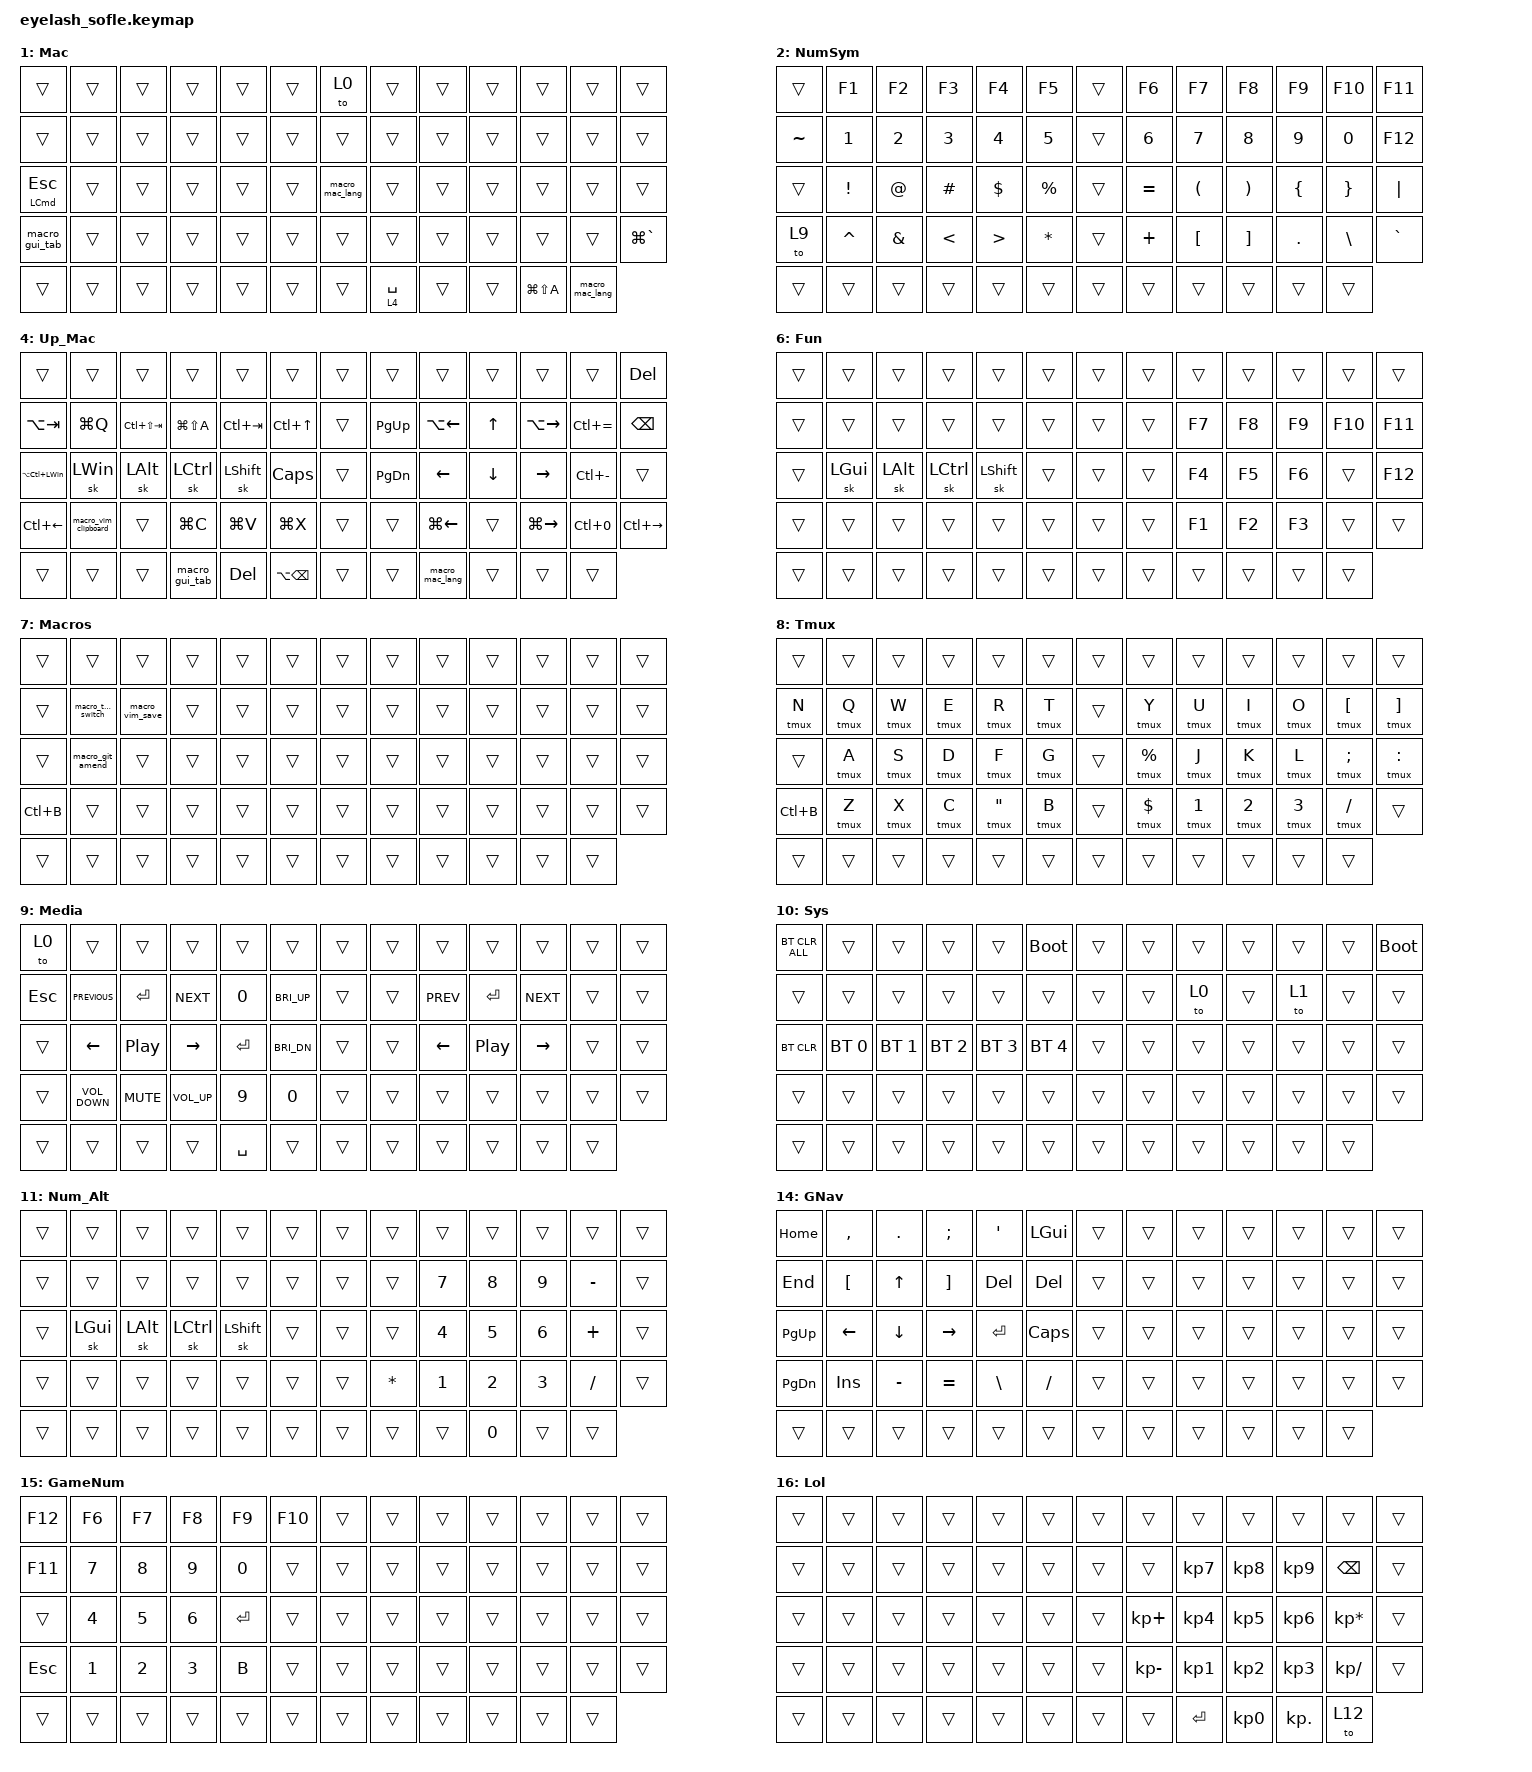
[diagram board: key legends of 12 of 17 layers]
#define ZMK_POINTING_DEFAULT_MOVE_VAL 1200  // 600
#define ZMK_POINTING_DEFAULT_SCRL_VAL 25   // 10

#include <input/processors.dtsi>
#include <zephyr/dt-bindings/input/input-event-codes.h>
#include <behaviors/tempo.dtsi>
#include <behaviors.dtsi>
#include <dt-bindings/zmk/bt.h>
#include <dt-bindings/zmk/keys.h>
#include <dt-bindings/zmk/pointing.h>

&mmv_input_listener { input-processors = <&zip_xy_scaler 2 1>; };

&msc_input_listener { input-processors = <&zip_scroll_scaler 2 1>; };

&msc {
    acceleration-exponent = <1>;      // 0
    time-to-max-speed-ms = <100>;       // 300
    delay-ms = <0>;                   // 0
};

&mmv {
    time-to-max-speed-ms = <500>;
    acceleration-exponent = <1>;
    trigger-period-ms = <16>;
};

&sk { quick-release; };

/ {
    scroll_encoder: scroll_encoder {
        compatible = "zmk,behavior-sensor-rotate";
        #sensor-binding-cells = <0>;
        bindings = <&msc SCRL_DOWN>, <&msc SCRL_UP>;

        tap-ms = <100>;
    };

    hml: homerow_mods_left {
        compatible = "zmk,behavior-hold-tap";
        label = "HOMEROW_MODS_LEFT_HAND";
        bindings = <&kp>, <&kp>;

        #binding-cells = <2>;
        tapping-term-ms = <200>;
        quick-tap-ms = <175>;
        require-prior-idle-ms = <115>;
        flavor = "balanced";
        hold-trigger-key-positions = <7 20 33 46 47 48 49 50 51 38 37 35 36 34 21 22 23 24 25 12 11 10 9 8 60 61 62 63 59>;
        hold-trigger-on-release;
    };

    hmr: homerow_mods_right {
        compatible = "zmk,behavior-hold-tap";
        label = "HOMEROW_MODS_RIGHT_HAND";
        bindings = <&kp>, <&kp>;

        #binding-cells = <2>;
        tapping-term-ms = <200>;
        quick-tap-ms = <175>;
        require-prior-idle-ms = <115>;
        flavor = "balanced";
        hold-trigger-key-positions = <0 1 2 3 4 5 13 14 15 16 17 18 26 27 28 29 30 31 39 40 41 42 43 44 53 54 55 56 57>;
        hold-trigger-on-release;
    };

    layer_mt: layer_mt {
        compatible = "zmk,behavior-hold-tap";
        label = "LAYER_MT";
        bindings = <&kp>, <&to>;

        #binding-cells = <2>;
        tapping-term-ms = <200>;
    };

    lt_prefer_tap: lt_prefer_tap {
        compatible = "zmk,behavior-hold-tap";
        label = "LT_PREFER_TAP";
        bindings = <&mo>, <&kp>;

        #binding-cells = <2>;
        tapping-term-ms = <200>;
        require-prior-idle-ms = <75>;
        flavor = "tap-preferred";
    };

    lt_prefer_hold: lt_prefer_hold {
        compatible = "zmk,behavior-hold-tap";
        label = "LT_PREFER_HOLD";
        bindings = <&mo>, <&kp>;

        #binding-cells = <2>;
        tapping-term-ms = <150>;
        flavor = "hold-preferred";
        hold-while-undecided;
    };

    mt_prefer_tap: mt_prefer_tap {
        compatible = "zmk,behavior-hold-tap";
        label = "MT_PREFER_TAP";
        bindings = <&kp>, <&kp>;

        #binding-cells = <2>;
        tapping-term-ms = <200>;
        flavor = "tap-preferred";
        require-prior-idle-ms = <75>;
    };

    behaviors {
    };

    macros {
        macro_git_amend: macro_git_amend {
            compatible = "zmk,behavior-macro";
            #binding-cells = <0>;
            bindings = <&none &kp G &kp I &kp T &kp SPACE &kp C &kp O &kp M &kp M &kp I &kp T &kp SPACE &kp MINUS &kp MINUS &kp A &kp M &kp E &kp N &kp D &kp SPACE &kp MINUS &kp MINUS &kp N &kp O &kp MINUS &kp E &kp D &kp I &kp T>;
            label = "MACRO_GIT_AMEND";
            tap-ms = <5>;
        };

        macro_vim_save: macro_vim_save {
            compatible = "zmk,behavior-macro";
            #binding-cells = <0>;
            bindings = <&none &kp COLON &kp W &kp RET>;
            label = "MACRO_VIM_SAVE";
            wait-ms = <30>;
            tap-ms = <30>;
        };

        macro_vim_quit: macro_vim_quit {
            compatible = "zmk,behavior-macro";
            #binding-cells = <0>;
            bindings = <&none &kp COLON &kp Q &kp RET>;
            label = "MACRO_VIM_QUIT";
            wait-ms = <30>;
            tap-ms = <30>;
        };

        macro_tmux_switch: macro_tmux_switch {
            compatible = "zmk,behavior-macro";
            #binding-cells = <0>;
            bindings = <&none &kp LC(B) &kp Q>;
            label = "MACRO_TMUX_SWITCH";
        };

        macro_alt_tab: macro_alt_tab {
            compatible = "zmk,behavior-macro";
            #binding-cells = <0>;
            bindings =
                <&none>,
                <&macro_press>,
                <&kp LEFT_ALT &kp TAB &mo 3>,
                <&macro_release>,
                <&kp TAB>,
                <&macro_pause_for_release>,
                <&macro_release>,
                <&kp LEFT_ALT &mo 3>;

            label = "MACRO_ALT_TAB";
        };

        macro_gui_tab: macro_gui_tab {
            compatible = "zmk,behavior-macro";
            #binding-cells = <0>;
            bindings =
                <&none>,
                <&macro_press>,
                <&kp LEFT_WIN &kp TAB &mo 4>,
                <&macro_release>,
                <&kp TAB>,
                <&macro_pause_for_release>,
                <&macro_release>,
                <&kp LEFT_WIN &mo 4>;

            label = "MACRO_GUI_TAB";
        };

        tmux: tmux {
            compatible = "zmk,behavior-macro-one-param";
            #binding-cells = <1>;
            bindings = <&none &kp LC(B) &macro_param_1to1 &kp MACRO_PLACEHOLDER>;
            label = "TMUX";
        };

        macro_vim_clipboard: macro_vim_clipboard {
            compatible = "zmk,behavior-macro";
            #binding-cells = <0>;
            bindings = <&none &kp DQT &kp PLUS>;
            label = "MACRO_VIM_CLIPBOARD";
        };

        macro_win_lang: macro_win_lang {
            compatible = "zmk,behavior-macro";
            #binding-cells = <0>;
            bindings =
                <&none>,
                <&macro_press>,
                <&kp LEFT_WIN &kp SPACE>,
                <&macro_release>,
                <&kp SPACE>,
                <&macro_pause_for_release>,
                <&macro_release>,
                <&kp LEFT_WIN>;

            label = "MACRO_WIN_LANG";
        };

        macro_mac_lang: macro_mac_lang {
            compatible = "zmk,behavior-macro";
            #binding-cells = <0>;
            bindings = <&none &kp LC(SLASH)>;
            label = "MACRO_MAC_LANG";
        };
    };

    combos {
        compatible = "zmk,combos";

        combo_vim_save {
            bindings = <&macro_vim_save>;
            key-positions = <14 15>;
            layers = <0 1>;
        };

        combo_vim_quit {
            bindings = <&macro_vim_quit>;
            key-positions = <13 14>;
            layers = <0 1>;
        };

        combo_right_shift {
            bindings = <&sk LEFT_SHIFT>;
            key-positions = <33 34>;
            layers = <0 1>;
        };

        combo_left_shift {
            bindings = <&sk LEFT_SHIFT>;
            key-positions = <31 30>;
            layers = <0 1>;
        };

        combo_cap_words {
            bindings = <&caps_word>;
            key-positions = <40 41>;
            layers = <0 1>;
        };

        combo_game {
            bindings = <&to 12>;
            key-positions = <53 54 55>;
            layers = <0>;
        };

        combo_game_reverse {
            bindings = <&to 0>;
            key-positions = <53 54 55>;
            layers = <12>;
        };
    };

    keymap {
        compatible = "zmk,keymap";

        Win {
            bindings = <
&kp GRAVE                           &kp N1           &kp N2           &kp N3               &kp N4             &kp N5                         &to 1            &kp N6                  &kp N7              &kp N8               &kp N9           &kp N0              &kp MINUS
&kp TAB                             &kp Q            &kp W            &kp E                &kp R              &kp T                          &to 12           &kp Y                   &kp U               &kp I                &kp O            &kp P               &kp BSLH
&mt_prefer_tap LEFT_CONTROL ESCAPE  &hml LEFT_WIN A  &hml LEFT_ALT S  &hml LEFT_CONTROL D  &hml LEFT_SHIFT F  &kp G                          &macro_win_lang  &kp H                   &hmr RIGHT_SHIFT J  &hmr LEFT_CONTROL K  &hmr LEFT_ALT L  &hmr LEFT_WIN SEMI  &kp APOS
&macro_alt_tab                      &kp Z            &kp X            &kp C                &kp V              &kp B                          &kp LG(LS(S))    &kp N                   &kp M               &kp COMMA            &kp DOT          &kp FSLH            &kp LC(LG(LA(LS(TAB))))
&kp C_MUTE                          &none            &none            &lt 6 LEFT_ALT       &lt 5 ENTER        &lt_prefer_hold 2 BACKSPACE    &to 12           &lt_prefer_tap 3 SPACE  &mo 7               &lt 9 LEFT_WIN       &kp LA(A)        &macro_win_lang
            >;

            sensor-bindings = <&inc_dec_kp C_VOLUME_UP C_VOL_DN>;
            display-name = "Base";
        };

        Mac {
            bindings = <
&trans                      &trans  &trans  &trans  &trans  &trans    &to 0            &trans                  &trans  &trans  &trans         &trans           &trans
&trans                      &trans  &trans  &trans  &trans  &trans    &trans           &trans                  &trans  &trans  &trans         &trans           &trans
&mt_prefer_tap LCMD ESCAPE  &trans  &trans  &trans  &trans  &trans    &macro_mac_lang  &trans                  &trans  &trans  &trans         &trans           &trans
&macro_gui_tab              &trans  &trans  &trans  &trans  &trans    &trans           &trans                  &trans  &trans  &trans         &trans           &kp LG(GRAVE)
&trans                      &trans  &trans  &trans  &trans  &trans    &trans           &lt_prefer_tap 4 SPACE  &trans  &trans  &kp LG(LS(A))  &macro_mac_lang
            >;

            display-name = "Mac";
        };

        NumSym {
            bindings = <
&trans     &kp F1           &kp F2         &kp F3         &kp F4            &kp F5          &trans  &kp F6     &kp F7                &kp F8                 &kp F9          &kp F10          &kp F11
&kp TILDE  &kp N1           &kp N2         &kp N3         &kp N4            &kp N5          &trans  &kp N6     &kp N7                &kp N8                 &kp N9          &kp N0           &kp F12
&trans     &kp EXCLAMATION  &kp AT_SIGN    &kp HASH       &kp DOLLAR        &kp PERCENT     &trans  &kp EQUAL  &kp LEFT_PARENTHESIS  &kp RIGHT_PARENTHESIS  &kp LEFT_BRACE  &kp RIGHT_BRACE  &kp PIPE
&to 9      &kp CARET        &kp AMPERSAND  &kp LESS_THAN  &kp GREATER_THAN  &kp ASTERISK    &trans  &kp PLUS   &kp LEFT_BRACKET      &kp RIGHT_BRACKET      &kp PERIOD      &kp BACKSLASH    &kp GRAVE
&trans     &trans           &trans         &trans         &trans            &trans          &trans  &trans     &trans                &trans                 &trans          &trans
            >;

            display-name = "NumSym";
        };

        Up_Win {
            bindings = <
&trans                   &trans                &trans           &trans            &trans          &kp PRINTSCREEN      &trans  &trans         &trans              &trans        &trans               &trans         &kp DELETE
&kp LS(LA(LC(LG(TAB))))  &kp LA(F4)            &kp LC(LS(TAB))  &kp LC(LS(A))     &kp LC(TAB)     &kp LG(TAB)          &trans  &kp PAGE_UP    &kp LC(LEFT_ARROW)  &kp UP_ARROW  &kp LC(RIGHT_ARROW)  &kp LC(EQUAL)  &kp BACKSPACE
&kp LS(LEFT_WIN)         &sk LEFT_WIN          &sk LEFT_ALT     &sk LEFT_CONTROL  &sk LEFT_SHIFT  &kp CAPS             &trans  &kp PAGE_DOWN  &kp LEFT            &kp DOWN      &kp RIGHT_ARROW      &kp LC(MINUS)  &trans
&kp LC(LG(LEFT_ARROW))   &macro_vim_clipboard  &trans           &kp LC(C)         &kp LC(V)       &kp LC(X)            &trans  &trans         &kp HOME            &trans        &kp END              &kp LC(N0)     &kp LC(LG(RIGHT))
&trans                   &trans                &trans           &macro_alt_tab    &kp DELETE      &kp LC(BACKSPACE)    &trans  &trans         &macro_win_lang     &trans        &trans               &trans
            >;

            display-name = "Up_Win";
        };

        Up_Mac {
            bindings = <
&trans                &trans                &trans           &trans            &trans          &trans               &trans  &trans         &trans              &trans        &trans               &trans         &kp DELETE
&kp LA(TAB)           &kp LG(Q)             &kp LC(LS(TAB))  &kp LG(LS(A))     &kp LC(TAB)     &kp LC(UP_ARROW)     &trans  &kp PAGE_UP    &kp LA(LEFT_ARROW)  &kp UP_ARROW  &kp LA(RIGHT_ARROW)  &kp LC(EQUAL)  &kp BACKSPACE
&kp LA(LC(LEFT_WIN))  &sk LEFT_WIN          &sk LEFT_ALT     &sk LEFT_CONTROL  &sk LEFT_SHIFT  &kp CAPS             &trans  &kp PAGE_DOWN  &kp LEFT            &kp DOWN      &kp RIGHT_ARROW      &kp LC(MINUS)  &trans
&kp LC(LEFT)          &macro_vim_clipboard  &trans           &kp LG(C)         &kp LG(V)       &kp LG(X)            &trans  &trans         &kp LG(LEFT)        &trans        &kp LG(RIGHT)        &kp LC(N0)     &kp LC(RIGHT)
&trans                &trans                &trans           &macro_gui_tab    &kp DELETE      &kp LA(BACKSPACE)    &trans  &trans         &macro_mac_lang     &trans        &trans               &trans
            >;

            display-name = "Up_Mac";
        };

        Mouse {
            bindings = <
&trans  &trans                        &trans    &trans     &trans     &trans    &mmv MOVE_UP     &trans          &trans          &trans          &trans           &trans     &trans
&trans  &kp LS(LA(LC(LG(NUMBER_1))))  &trans    &trans     &trans     &trans    &mmv MOVE_DOWN   &msc SCRL_UP    &trans          &mmv MOVE_UP    &trans           &trans     &trans
&trans  &kp LGUI                      &kp LALT  &kp LCTRL  &kp LSHFT  &trans    &mmv MOVE_LEFT   &msc SCRL_DOWN  &mmv MOVE_LEFT  &mmv MOVE_DOWN  &mmv MOVE_RIGHT  &mkp LCLK  &mkp RCLK
&trans  &trans                        &trans    &trans     &trans     &trans    &mmv MOVE_RIGHT  &trans          &trans          &trans          &trans           &trans     &trans
&trans  &trans                        &trans    &trans     &trans     &trans    &mkp LCLK        &trans          &trans          &trans          &trans           &trans
            >;

            display-name = "Mouse";
        };

        Fun {
            bindings = <
&trans  &trans    &trans    &trans     &trans     &trans    &trans  &trans  &trans  &trans  &trans  &trans   &trans
&trans  &trans    &trans    &trans     &trans     &trans    &trans  &trans  &kp F7  &kp F8  &kp F9  &kp F10  &kp F11
&trans  &sk LGUI  &sk LALT  &sk LCTRL  &sk LSHFT  &trans    &trans  &trans  &kp F4  &kp F5  &kp F6  &trans   &kp F12
&trans  &trans    &trans    &trans     &trans     &trans    &trans  &trans  &kp F1  &kp F2  &kp F3  &trans   &trans
&trans  &trans    &trans    &trans     &trans     &trans    &trans  &trans  &trans  &trans  &trans  &trans
            >;

            display-name = "Fun";
        };

        Macros {
            bindings = <
&trans     &trans              &trans           &trans  &trans  &trans    &trans  &trans  &trans  &trans  &trans  &trans  &trans
&trans     &macro_tmux_switch  &macro_vim_save  &trans  &trans  &trans    &trans  &trans  &trans  &trans  &trans  &trans  &trans
&trans     &macro_git_amend    &trans           &trans  &trans  &trans    &trans  &trans  &trans  &trans  &trans  &trans  &trans
&kp LC(B)  &trans              &trans           &trans  &trans  &trans    &trans  &trans  &trans  &trans  &trans  &trans  &trans
&trans     &trans              &trans           &trans  &trans  &trans    &trans  &trans  &trans  &trans  &trans  &trans
            >;

            display-name = "Macros";
        };

        Tmux {
            bindings = <
&trans     &trans   &trans   &trans   &trans               &trans     &trans  &trans         &trans    &trans    &trans    &trans      &trans
&tmux N    &tmux Q  &tmux W  &tmux E  &tmux R              &tmux T    &trans  &tmux Y        &tmux U   &tmux I   &tmux O   &tmux LBKT  &tmux RBKT
&trans     &tmux A  &tmux S  &tmux D  &tmux F              &tmux G    &trans  &tmux PERCENT  &tmux J   &tmux K   &tmux L   &tmux SEMI  &tmux COLON
&kp LC(B)  &tmux Z  &tmux X  &tmux C  &tmux DOUBLE_QUOTES  &tmux B    &trans  &tmux DOLLAR   &tmux N1  &tmux N2  &tmux N3  &tmux FSLH  &trans
&trans     &trans   &trans   &trans   &trans               &trans     &trans  &trans         &trans    &trans    &trans    &trans
            >;

            display-name = "Tmux";
        };

        Media {
            bindings = <
&to 0       &trans             &trans      &trans           &trans        &trans          &trans  &trans  &trans      &trans     &trans      &trans  &trans
&kp ESCAPE  &kp C_PREVIOUS     &kp ENTER   &kp C_NEXT       &kp NUMBER_0  &kp C_BRI_UP    &trans  &trans  &kp C_PREV  &kp ENTER  &kp C_NEXT  &trans  &trans
&trans      &kp LEFT_ARROW     &kp C_PP    &kp RIGHT        &kp ENTER     &kp C_BRI_DN    &trans  &trans  &kp LEFT    &kp C_PP   &kp RIGHT   &trans  &trans
&trans      &kp C_VOLUME_DOWN  &kp C_MUTE  &kp C_VOLUME_UP  &kp NUMBER_9  &kp NUMBER_0    &trans  &trans  &trans      &trans     &trans      &trans  &trans
&trans      &trans             &trans      &trans           &kp SPACE     &trans          &trans  &trans  &trans      &trans     &trans      &trans
            >;

            display-name = "Media";
        };

        Sys {
            bindings = <
&bt BT_CLR_ALL  &trans        &trans        &trans        &trans        &bootloader     &trans  &trans  &trans  &trans  &trans  &trans  &bootloader
&trans          &trans        &trans        &trans        &trans        &trans          &trans  &trans  &to 0   &trans  &to 1   &trans  &trans
&bt BT_CLR      &bt BT_SEL 0  &bt BT_SEL 1  &bt BT_SEL 2  &bt BT_SEL 3  &bt BT_SEL 4    &trans  &trans  &trans  &trans  &trans  &trans  &trans
&trans          &trans        &trans        &trans        &trans        &trans          &trans  &trans  &trans  &trans  &trans  &trans  &trans
&trans          &trans        &trans        &trans        &trans        &trans          &trans  &trans  &trans  &trans  &trans  &trans
            >;

            display-name = "Sys";
        };

        Num_Alt {
            bindings = <
&trans  &trans    &trans    &trans     &trans     &trans    &trans  &trans        &trans  &trans  &trans  &trans     &trans
&trans  &trans    &trans    &trans     &trans     &trans    &trans  &trans        &kp N7  &kp N8  &kp N9  &kp MINUS  &trans
&trans  &sk LGUI  &sk LALT  &sk LCTRL  &sk LSHFT  &trans    &trans  &trans        &kp N4  &kp N5  &kp N6  &kp PLUS   &trans
&trans  &trans    &trans    &trans     &trans     &trans    &trans  &kp ASTERISK  &kp N1  &kp N2  &kp N3  &kp FSLH   &trans
&trans  &trans    &trans    &trans     &trans     &trans    &trans  &trans        &trans  &kp N0  &trans  &trans
            >;

            display-name = "Num_Alt";
        };

        Game {
            bindings = <
&kp GRAVE  &kp N1         &kp N2  &kp N3  &kp N4     &kp N5    &trans              &kp N6     &kp N7     &kp N8     &kp N9   &kp N0    &kp F12
&kp TAB    &kp Q          &kp W   &kp E   &kp R      &kp T     &tog 14             &kp Y      &kp U      &kp I      &kp O    &kp P     &kp BSLH
&kp LCTRL  &kp A          &kp S   &kp D   &kp F      &kp G     &kp LC(LA(LS(F2)))  &kp H      &kp J      &kp K      &kp L    &kp SEMI  &kp APOS
&kp LSHFT  &kp Z          &kp X   &kp C   &kp V      &kp B     &kp LC(LA(LS(F1)))  &kp N      &kp M      &kp COMMA  &kp DOT  &kp FSLH  &kp RSHFT
&trans     &kp BACKSPACE  &mo 14  &mo 15  &kp SPACE  &mo 13    &to 0               &kp SPACE  &kp ENTER  &kp ENTER  &kp F16  &kp F15
            >;

            label = "Game";
        };

        Game_Alt {
            bindings = <
&kp F9  &kp F1     &kp F2          &kp F3  &kp F4  &kp F5    &kp LS(LA(LC(LG(BACKSLASH))))  &kp F6  &kp F7  &kp F8  &kp F9  &kp F10  &kp F11
&kp N   &kp J      &kp I           &kp O   &kp H   &kp P     &kp LS(LA(LC(LG(SQT))))        &trans  &trans  &trans  &trans  &trans   &kp F12
&kp N4  &kp N1     &kp N2          &kp N3  &kp N5  &kp L     &trans                         &trans  &trans  &trans  &trans  &trans   &trans
&kp M   &kp COMMA  &kp DOT         &kp U   &kp K   &kp Y     &kp D                          &trans  &trans  &trans  &trans  &trans   &kt DELETE
&trans  &trans     &kt LEFT_SHIFT  &trans  &trans  &trans    &kp LS(LA(LC(LG(SEMICOLON))))  &trans  &trans  &trans  &trans  &trans
            >;

            label = "GAlt";
        };

        Game_Nav {
            bindings = <
&kp HOME       &kp COMMA       &kp DOT       &kp SEMI   &kp APOS       &kp LGUI      &trans  &trans  &trans  &trans  &trans  &trans  &trans
&kp END        &kp LBKT        &kp UP_ARROW  &kp RBKT   &kp DELETE     &kp DELETE    &trans  &trans  &trans  &trans  &trans  &trans  &trans
&kp PAGE_UP    &kp LEFT_ARROW  &kp DOWN      &kp RIGHT  &kp ENTER      &kp CAPS      &trans  &trans  &trans  &trans  &trans  &trans  &trans
&kp PAGE_DOWN  &kp INS         &kp MINUS     &kp EQUAL  &kp BACKSLASH  &kp FSLH      &trans  &trans  &trans  &trans  &trans  &trans  &trans
&trans         &trans          &trans        &trans     &trans         &trans        &trans  &trans  &trans  &trans  &trans  &trans
            >;

            label = "GNav";
        };

        GameNum {
            bindings = <
&kp F12     &kp F6  &kp F7  &kp F8  &kp F9     &kp F10    &trans  &trans  &trans  &trans  &trans  &trans  &trans
&kp F11     &kp N7  &kp N8  &kp N9  &kp N0     &trans     &trans  &trans  &trans  &trans  &trans  &trans  &trans
&trans      &kp N4  &kp N5  &kp N6  &kp ENTER  &trans     &trans  &trans  &trans  &trans  &trans  &trans  &trans
&kp ESCAPE  &kp N1  &kp N2  &kp N3  &kp B      &trans     &trans  &trans  &trans  &trans  &trans  &trans  &trans
&trans      &trans  &trans  &trans  &trans     &trans     &trans  &trans  &trans  &trans  &trans  &trans
            >;

            label = "GameNum";
        };

        Lol {
            bindings = <
&trans  &trans  &trans  &trans  &trans  &trans    &trans  &trans           &trans           &trans           &trans           &trans           &trans
&trans  &trans  &trans  &trans  &trans  &trans    &trans  &trans           &kp KP_NUMBER_7  &kp KP_NUMBER_8  &kp KP_NUMBER_9  &kp BSPC         &trans
&trans  &trans  &trans  &trans  &trans  &trans    &trans  &kp KP_PLUS      &kp KP_NUMBER_4  &kp KP_NUMBER_5  &kp KP_NUMBER_6  &kp KP_ASTERISK  &trans
&trans  &trans  &trans  &trans  &trans  &trans    &trans  &kp KP_SUBTRACT  &kp KP_NUMBER_1  &kp KP_NUMBER_2  &kp KP_NUMBER_3  &kp KP_DIVIDE    &trans
&trans  &trans  &trans  &trans  &trans  &trans    &trans  &trans           &kp ENTER        &kp KP_NUMBER_0  &kp KP_DOT       &to 12
            >;

            label = "Lol";
        };
    };

    conditional_layers {
        compatible = "zmk,conditional-layers";

        to_sym {
            if-layers = <6 9>;
            then-layer = <10>;
        };

        tmux {
            if-layers = <5 7>;
            then-layer = <8>;
        };

        num_alt {
            if-layers = <6 7>;
            then-layer = <11>;
        };
    };
};
